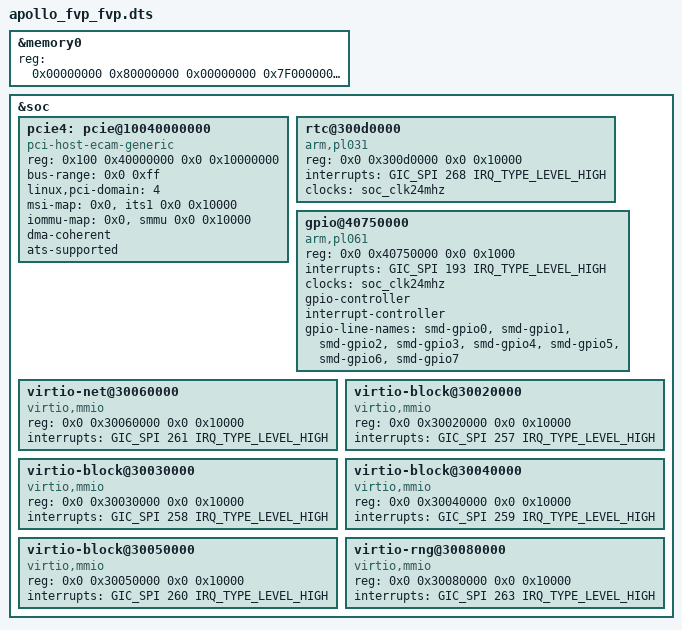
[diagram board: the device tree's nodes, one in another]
/*
 * Copyright (c) 2026, Arm Limited. All rights reserved.
 *
 * SPDX-License-Identifier: BSD-3-Clause
 */

/dts-v1/;

#include "apollo_fvp.dtsi"

&memory0 {
	/*
	 * FVP memory map:
	 * - Bank 0: start = 0x0000_0000_8000_0000, size = ~2 GiB (0x7F00_0000)
	 * - Bank 1: start = 0x0000_0200_0000_0000, size = 2 GiB (0x8000_0000)
	 */
	reg = <
		0x00000000  0x80000000  0x00000000  0x7F000000
		0x00000200  0x00000000  0x00000000  0x80000000
	>;
};

&soc {
	pcie4: pcie@10040000000 {
		compatible = "pci-host-ecam-generic";
		device_type = "pci";
		#address-cells = <3>;
		#size-cells = <2>;
		reg = <0x100 0x40000000 0x0 0x10000000>;
		bus-range = <0x0 0xff>;
		linux,pci-domain = <4>;
		ranges = <0x02000000 0x0 0x60000000
			  0x0 0x60000000 0x0 0x20000000>,
			 <0x43000000 0x101 0x60000000
			  0x101 0x60000000 0x0 0x20000000>;
		msi-map = <0x0 &its1 0x0 0x10000>;
		iommu-map = <0x0 &smmu 0x0 0x10000>;
		dma-coherent;
		ats-supported;
	};

	rtc@300d0000 {
		compatible = "arm,pl031", "arm,primecell";
		reg = <0x0 0x300d0000 0x0 0x10000>;
		interrupts = <GIC_SPI 268 IRQ_TYPE_LEVEL_HIGH>;
		clocks = <&soc_clk24mhz>;
		clock-names = "apb_pclk";
	};

	gpio@40750000 {
		compatible = "arm,pl061", "arm,primecell";
		reg = <0x0 0x40750000 0x0 0x1000>;
		interrupts = <GIC_SPI 193 IRQ_TYPE_LEVEL_HIGH>;
		clocks = <&soc_clk24mhz>;
		clock-names = "apb_pclk";
		gpio-controller;
		#gpio-cells = <2>;
		interrupt-controller;
		#interrupt-cells = <2>;
		gpio-line-names =
			"smd-gpio0", "smd-gpio1", "smd-gpio2", "smd-gpio3",
			"smd-gpio4", "smd-gpio5", "smd-gpio6", "smd-gpio7";
	};

	virtio-net@30060000 {
		compatible = "virtio,mmio";
		reg = <0x0 0x30060000 0x0 0x10000>;
		interrupts = <GIC_SPI 261 IRQ_TYPE_LEVEL_HIGH>;
	};

	/* OS storage */
	virtio-block@30020000 {
		compatible = "virtio,mmio";
		reg = <0x0 0x30020000 0x0 0x10000>;
		interrupts = <GIC_SPI 257 IRQ_TYPE_LEVEL_HIGH>;
	};

	/* Distro installation media */
	virtio-block@30030000 {
		compatible = "virtio,mmio";
		reg = <0x0 0x30030000 0x0 0x10000>;
		interrupts = <GIC_SPI 258 IRQ_TYPE_LEVEL_HIGH>;
	};

	/* SystemReady ACS validation media */
	virtio-block@30040000 {
		compatible = "virtio,mmio";
		reg = <0x0 0x30040000 0x0 0x10000>;
		interrupts = <GIC_SPI 259 IRQ_TYPE_LEVEL_HIGH>;
	};

	/* User data media */
	virtio-block@30050000 {
		compatible = "virtio,mmio";
		reg = <0x0 0x30050000 0x0 0x10000>;
		interrupts = <GIC_SPI 260 IRQ_TYPE_LEVEL_HIGH>;
	};

	virtio-rng@30080000 {
		compatible = "virtio,mmio";
		reg = <0x0 0x30080000 0x0 0x10000>;
		interrupts = <GIC_SPI 263 IRQ_TYPE_LEVEL_HIGH>;
	};
};
